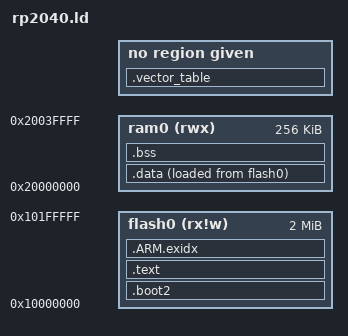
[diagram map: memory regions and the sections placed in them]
/*
 * This file was auto-generated by microzig
 *
 * Target CPU:  ARM Cortex-M0+
 * Target Chip: RP2040
 */

MEMORY
{
  flash0 (rx!w) : ORIGIN = 0x10000000, LENGTH = 0x00200000
  ram0   (rwx) : ORIGIN = 0x20000000, LENGTH = 0x00040000
}

SECTIONS
{
  .boot2 : {
    __boot2_start__ = .;
    KEEP (*(.boot2))
    __boot2_end__ = .;
  } > flash0

  /* ASSERT(__boot2_end__ - __boot2_start__ == 256, */
  /*   "ERROR: Pico second stage bootloader must be 256 bytes in size") */

  .vector_table :
  {
     KEEP(*(.vector_table))
  }

  .text :
  {
     *(.text*)
     *(.rodata*)
  } > flash0

  .ARM.exidx : {
      *(.ARM.exidx* .gnu.linkonce.armexidx.*)
  } >flash0

  .data :
  {
     _data_start = .;
     KEEP(*(.time_critical*))
     *(.data*)
     _data_end = .;
  } > ram0 AT> flash0

  .bss (NOLOAD) :
  {
     _bss_start = .;
      *(.bss*)
      _bss_end = .;
  } > ram0

  _data_load_start = LOADADDR(.data);
}
